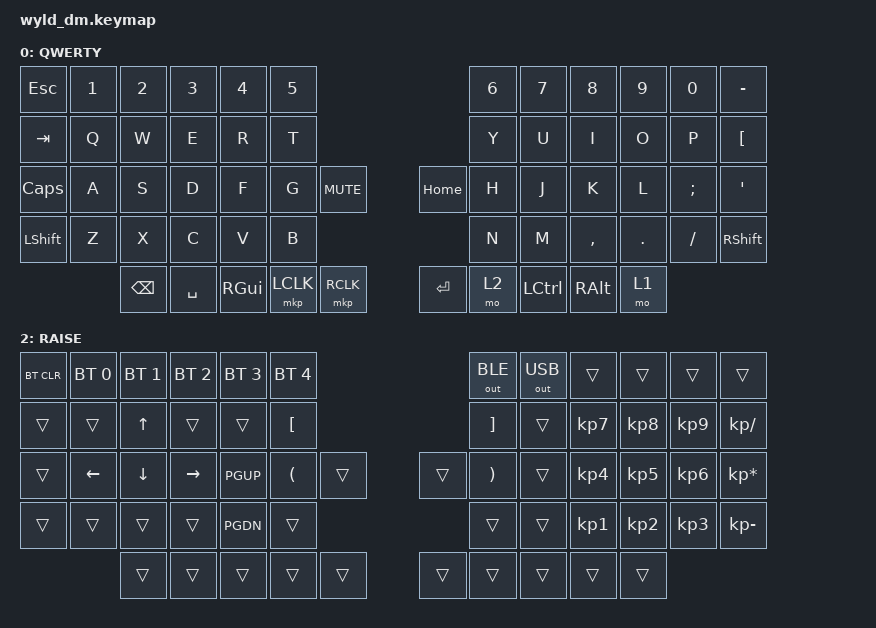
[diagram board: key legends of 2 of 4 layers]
/*
 * Copyright (c) 2020 The ZMK Contributors
 *
 * SPDX-License-Identifier: MIT
 */

#include <dt-bindings/led/led.h>
#include <dt-bindings/zmk/mouse.h>
#include <behaviors/mouse_keys.dtsi>
#include <behaviors.dtsi>
#include <dt-bindings/zmk/bt.h>
#include <dt-bindings/zmk/keys.h>
#include <dt-bindings/zmk/outputs.h>
#include <dt-bindings/zmk/rgb.h>

#define QWERTY 0
#define LOWER 1
#define RAISE 2

//# 4x6 with encoders

/ {
    behaviors {
        rgb_encoder_bright: rgb_encoder_bright {
            compatible = "zmk,behavior-sensor-rotate";
            #sensor-binding-cells = <0>;
            bindings = <&rgb_ug RGB_BRI>, <&rgb_ug RGB_BRD>;
        };

        rgb_encoder_hue: rgb_encoder_hue {
            compatible = "zmk,behavior-sensor-rotate";
            #sensor-binding-cells = <0>;
            bindings = <&rgb_ug RGB_HUI>, <&rgb_ug RGB_HUD>;
        };
    };

    keymap {
        compatible = "zmk,keymap";

        default_layer {
            display-name = "QWERTY";
            bindings = <
&kp ESC        &kp N1     &kp N2    &kp N3     &kp N4     &kp N5                 &kp N6     &kp N7    &kp N8     &kp N9   &kp N0    &kp MINUS
&kp TAB        &kp Q      &kp W     &kp E      &kp R      &kp T                  &kp Y      &kp U     &kp I      &kp O    &kp P     &kp LBKT
&kp CAPS       &kp A      &kp S     &kp D      &kp F      &kp G      &kp K_MUTE  &kp HOME   &kp H     &kp J      &kp K    &kp L     &kp SEMI   &kp SQT
&kp LSHFT      &kp Z      &kp X     &kp C      &kp V      &kp B                  &kp N      &kp M     &kp COMMA  &kp DOT  &kp FSLH  &kp RSHFT
&kp BACKSPACE  &kp SPACE  &kp RGUI  &mkp LCLK  &mkp RCLK  &kp ENTER  &mo 2       &kp LCTRL  &kp RALT  &mo 1
            >;

            sensor-bindings = <&inc_dec_kp C_VOL_DN C_VOL_UP &inc_dec_kp PG_UP PG_DN>;
        };

        lower_layer {
            display-name = "LOWER";
            bindings = <
&trans       &kp F1    &kp F2  &kp F3      &kp F4      &kp F5                      &kp F6           &kp F7    &kp F8           &kp F9       &kp F10   &kp F11
&kp GRAVE    &kp EXCL  &kp AT  &kp HASH    &kp DOLLAR  &kp PRCNT                   &kp CARET        &kp AMPS  &kp KP_MULTIPLY  &kp LPAR     &kp RPAR  &kp F12
&bootloader  &trans    &trans  &trans      &trans      &trans     &rgb_ug RGB_TOG  &rgb_ug RGB_EFF  &trans    &kp MINUS        &kp KP_PLUS  &kp LBRC  &kp RBRC  &bootloader
&trans       &trans    &trans  &trans      &trans      &trans                      &trans           &trans    &trans           &trans       &kp PIPE  &trans
&trans       &trans    &trans  &kp DELETE  &trans      &trans     &trans           &trans           &trans
            >;

            sensor-bindings = <&rgb_encoder_bright &rgb_encoder_hue>;
        };

        raise_layer {
            display-name = "RAISE";
            bindings = <
&bt BT_CLR  &bt BT_SEL 0    &bt BT_SEL 1    &bt BT_SEL 2     &bt BT_SEL 3  &bt BT_SEL 4          &out OUT_BLE  &out OUT_USB  &trans     &trans     &trans     &trans
&trans      &trans          &kp UP_ARROW    &trans           &trans        &kp LBKT              &kp RBKT      &trans        &kp KP_N7  &kp KP_N8  &kp KP_N9  &kp KP_DIVIDE
&trans      &kp LEFT_ARROW  &kp DOWN_ARROW  &kp RIGHT_ARROW  &kp PGUP      &kp LPAR      &trans  &trans        &kp RPAR      &trans     &kp KP_N4  &kp KP_N5  &kp KP_N6      &kp KP_MULTIPLY
&trans      &trans          &trans          &trans           &kp PGDN      &trans                &trans        &trans        &kp KP_N1  &kp KP_N2  &kp KP_N3  &kp KP_MINUS
&trans      &trans          &trans          &trans           &trans        &trans        &trans  &trans        &trans        &trans
            >;

            sensor-bindings = <&inc_dec_kp C_VOL_DN C_VOL_UP &inc_dec_kp PG_UP PG_DN>;
        };

        mouse_layer {
            display-name = "MOUSE";
            bindings = <
&trans  &trans  &trans  &trans  &trans  &trans          &trans     &trans     &trans  &trans  &trans  &trans
&trans  &trans  &trans  &trans  &trans  &trans          &trans     &trans     &trans  &trans  &trans  &trans
&trans  &trans  &trans  &trans  &trans  &trans  &trans  &trans     &trans     &trans  &trans  &trans  &trans  &trans
&trans  &trans  &trans  &trans  &trans  &trans          &mkp LCLK  &mkp RCLK  &trans  &trans  &trans  &trans
&trans  &trans  &trans  &trans  &trans  &trans  &trans  &trans
            >;

            sensor-bindings = <&inc_dec_kp C_VOL_DN C_VOL_UP &inc_dec_kp PG_UP PG_DN>;
        };
    };
};

&led_strip { chain-length = <40>; };
